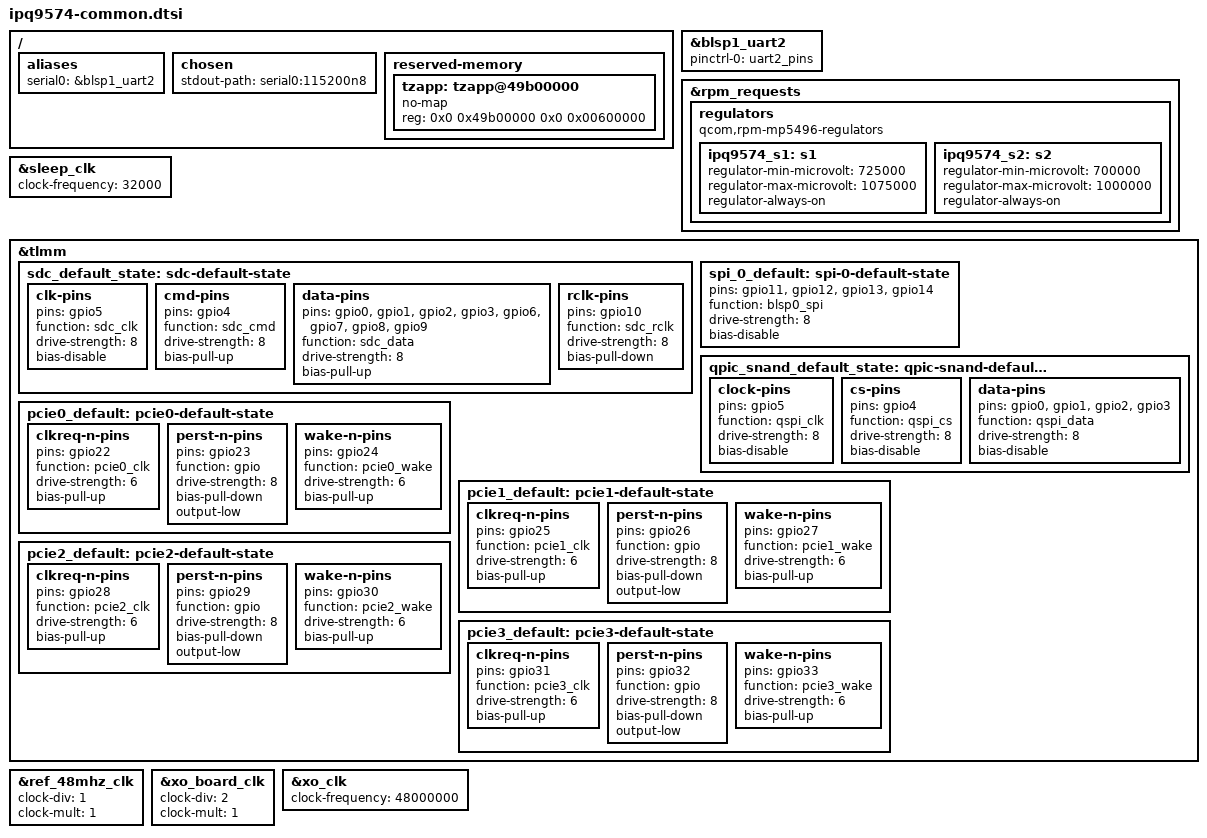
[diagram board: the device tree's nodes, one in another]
// SPDX-License-Identifier: (GPL-2.0+ OR BSD-3-Clause)

#include "ipq9574.dtsi"

#include <dt-bindings/gpio/gpio.h>
#include <dt-bindings/input/input.h>
#include <dt-bindings/leds/common.h>

/ {
	aliases {
		serial0 = &blsp1_uart2;
	};

	chosen {
		stdout-path = "serial0:115200n8";
	};

	reserved-memory {
		tzapp: tzapp@49b00000 {
			no-map;
			reg = <0x0 0x49b00000 0x0 0x00600000>;
		};
	};
};

&blsp1_uart2 {
	pinctrl-0 = <&uart2_pins>;
	pinctrl-names = "default";
	status = "okay";
};

&rpm_requests {
	regulators {
		compatible = "qcom,rpm-mp5496-regulators";

		/* Keep the CPU rail at or above its 725 mV SVS voltage. */
		ipq9574_s1: s1 {
			regulator-min-microvolt = <725000>;
			regulator-max-microvolt = <1075000>;
			regulator-always-on;
		};

		ipq9574_s2: s2 {
			regulator-min-microvolt = <700000>;
			regulator-max-microvolt = <1000000>;
			regulator-always-on;
		};
	};
};

&sleep_clk {
	clock-frequency = <32000>;
};

&tlmm {
	/* Unused pin groups must not appear in the board DTB. */
	/omit-if-no-ref/ sdc_default_state: sdc-default-state {
		clk-pins {
			pins = "gpio5";
			function = "sdc_clk";
			drive-strength = <8>;
			bias-disable;
		};

		cmd-pins {
			pins = "gpio4";
			function = "sdc_cmd";
			drive-strength = <8>;
			bias-pull-up;
		};

		data-pins {
			pins = "gpio0", "gpio1", "gpio2", "gpio3",
			       "gpio6", "gpio7", "gpio8", "gpio9";
			function = "sdc_data";
			drive-strength = <8>;
			bias-pull-up;
		};

		rclk-pins {
			pins = "gpio10";
			function = "sdc_rclk";
			drive-strength = <8>;
			bias-pull-down;
		};
	};

	/omit-if-no-ref/ spi_0_default: spi-0-default-state {
		pins = "gpio11", "gpio12", "gpio13", "gpio14";
		function = "blsp0_spi";
		drive-strength = <8>;
		bias-disable;
	};

	/omit-if-no-ref/ qpic_snand_default_state: qpic-snand-default-state {
		clock-pins {
			pins = "gpio5";
			function = "qspi_clk";
			drive-strength = <8>;
			bias-disable;
		};

		cs-pins {
			pins = "gpio4";
			function = "qspi_cs";
			drive-strength = <8>;
			bias-disable;
		};

		data-pins {
			pins = "gpio0", "gpio1", "gpio2", "gpio3";
			function = "qspi_data";
			drive-strength = <8>;
			bias-disable;
		};
	};

	/omit-if-no-ref/ pcie0_default: pcie0-default-state {
		clkreq-n-pins {
			pins = "gpio22";
			function = "pcie0_clk";
			drive-strength = <6>;
			bias-pull-up;
		};

		perst-n-pins {
			pins = "gpio23";
			function = "gpio";
			drive-strength = <8>;
			bias-pull-down;
			output-low;
		};

		wake-n-pins {
			pins = "gpio24";
			function = "pcie0_wake";
			drive-strength = <6>;
			bias-pull-up;
		};
	};

	/omit-if-no-ref/ pcie1_default: pcie1-default-state {
		clkreq-n-pins {
			pins = "gpio25";
			function = "pcie1_clk";
			drive-strength = <6>;
			bias-pull-up;
		};

		perst-n-pins {
			pins = "gpio26";
			function = "gpio";
			drive-strength = <8>;
			bias-pull-down;
			output-low;
		};

		wake-n-pins {
			pins = "gpio27";
			function = "pcie1_wake";
			drive-strength = <6>;
			bias-pull-up;
		};
	};

	/omit-if-no-ref/ pcie2_default: pcie2-default-state {
		clkreq-n-pins {
			pins = "gpio28";
			function = "pcie2_clk";
			drive-strength = <6>;
			bias-pull-up;
		};

		perst-n-pins {
			pins = "gpio29";
			function = "gpio";
			drive-strength = <8>;
			bias-pull-down;
			output-low;
		};

		wake-n-pins {
			pins = "gpio30";
			function = "pcie2_wake";
			drive-strength = <6>;
			bias-pull-up;
		};
	};

	/omit-if-no-ref/ pcie3_default: pcie3-default-state {
		clkreq-n-pins {
			pins = "gpio31";
			function = "pcie3_clk";
			drive-strength = <6>;
			bias-pull-up;
		};

		perst-n-pins {
			pins = "gpio32";
			function = "gpio";
			drive-strength = <8>;
			bias-pull-down;
			output-low;
		};

		wake-n-pins {
			pins = "gpio33";
			function = "pcie3_wake";
			drive-strength = <6>;
			bias-pull-up;
		};
	};
};

/* Wi-Fi provides a 48 MHz reference; the GCC input is divided to 24 MHz. */
&ref_48mhz_clk {
	clock-div = <1>;
	clock-mult = <1>;
};

&xo_board_clk {
	clock-div = <2>;
	clock-mult = <1>;
};

&xo_clk {
	clock-frequency = <48000000>;
};
